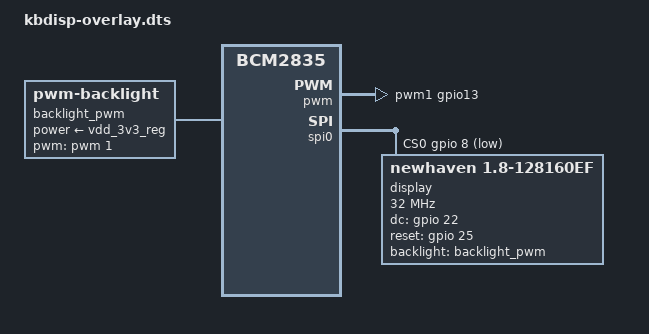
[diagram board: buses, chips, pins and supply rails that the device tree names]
/dts-v1/;
/plugin/;

#include <dt-bindings/gpio/gpio.h>

/ {
    compatible = "brcm,bcm2835";

    fragment@0 {
        target = <&pwm>;
        pwm_frag: __overlay__ {
            #pwm-cells = <2>;

            pinctrl-names = "default";
            pinctrl-0 = <&pwm1_gpio13>;
            assigned-clock-rates = <100000000>;
            status = "okay";
        };
    };


    fragment@1 {
        target-path = "/";
        __overlay__ {
            backlight_pwm: backlight0 {
                  compatible = "pwm-backlight";

                  pwms = <&pwm 1 2000000>;
                  brightness-levels = <0 4 8 16 32 64 128 255>;
                  default-brightness-level = <5>;
                  power-supply = <&vdd_3v3_reg>;
                  status = "okay";
            };
        };
    };


    fragment@2 {
            target = <&spidev0>;
            __overlay__ {
                    status = "disabled";
            };
    };

    fragment@3 {
        target = <&spi0>;

            __overlay__ {
            #address-cells = <1>;
            #size-cells = <0>;
            status = "okay";

            cs-gpios = <&gpio 8 GPIO_ACTIVE_LOW>;
            num-chipselects = <1>;

            display@0 {
                compatible = "newhaven,1.8-128160EF", "ilitek,ili9163";
                reg = <0>;
                spi-max-frequency = <32000000>;
                dc-gpios = <&gpio 22 GPIO_ACTIVE_HIGH>;
                reset-gpios = <&gpio 25 GPIO_ACTIVE_HIGH>;
                rotation = <270>;
                buswidth = <8>;
                spi-3wire;
                backlight = <&backlight_pwm>;
            };
        };
    };
};
